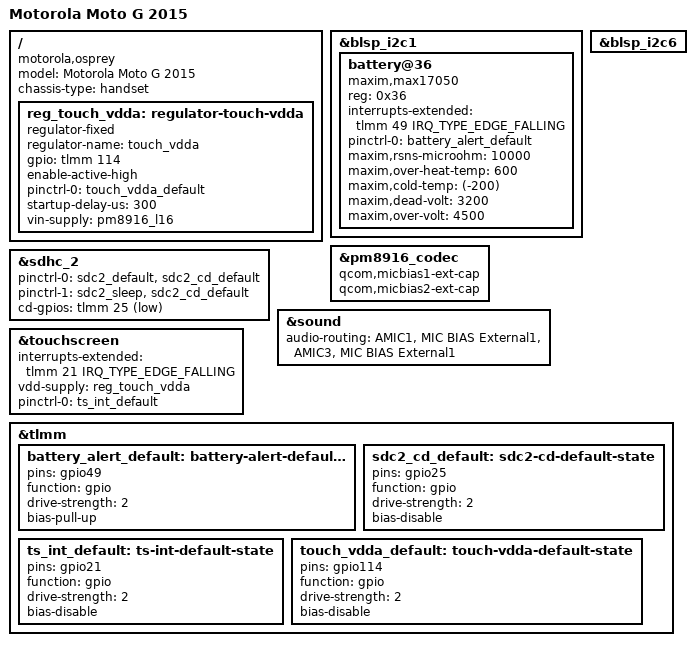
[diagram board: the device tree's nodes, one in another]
// SPDX-License-Identifier: GPL-2.0-only

/dts-v1/;

#include "msm8916-motorola-common.dtsi"

/ {
	model = "Motorola Moto G 2015";
	compatible = "motorola,osprey", "qcom,msm8916";
	chassis-type = "handset";

	reg_touch_vdda: regulator-touch-vdda {
		compatible = "regulator-fixed";
		regulator-name = "touch_vdda";
		gpio = <&tlmm 114 GPIO_ACTIVE_HIGH>;
		enable-active-high;
		pinctrl-0 = <&touch_vdda_default>;
		pinctrl-names = "default";
		startup-delay-us = <300>;
		vin-supply = <&pm8916_l16>;
	};
};

&blsp_i2c1 {
	status = "okay";

	battery@36 {
		compatible = "maxim,max17050";
		reg = <0x36>;

		interrupts-extended = <&tlmm 49 IRQ_TYPE_EDGE_FALLING>;

		pinctrl-0 = <&battery_alert_default>;
		pinctrl-names = "default";

		maxim,rsns-microohm = <10000>;
		maxim,over-heat-temp = <600>;
		maxim,cold-temp = <(-200)>;
		maxim,dead-volt = <3200>;
		maxim,over-volt = <4500>;

	};
};

&blsp_i2c6 {
	/* magnetometer@c */
};

&pm8916_codec {
	qcom,micbias1-ext-cap;
	qcom,micbias2-ext-cap;
};

&sdhc_2 {
	pinctrl-0 = <&sdc2_default &sdc2_cd_default>;
	pinctrl-1 = <&sdc2_sleep &sdc2_cd_default>;
	pinctrl-names = "default", "sleep";

	cd-gpios = <&tlmm 25 GPIO_ACTIVE_LOW>;
};

&sound {
	audio-routing =
		"AMIC1", "MIC BIAS External1",
		"AMIC3", "MIC BIAS External1";
};

&touchscreen {
	interrupts-extended = <&tlmm 21 IRQ_TYPE_EDGE_FALLING>;

	vdd-supply = <&reg_touch_vdda>;

	pinctrl-0 = <&ts_int_default>;
	pinctrl-names = "default";
};

&tlmm {
	battery_alert_default: battery-alert-default-state {
		pins = "gpio49";
		function = "gpio";
		drive-strength = <2>;
		bias-pull-up;
	};

	sdc2_cd_default: sdc2-cd-default-state {
		pins = "gpio25";
		function = "gpio";
		drive-strength = <2>;
		bias-disable;
	};

	ts_int_default: ts-int-default-state {
		pins = "gpio21";
		function = "gpio";
		drive-strength = <2>;
		bias-disable;
	};

	touch_vdda_default: touch-vdda-default-state {
		pins = "gpio114";
		function = "gpio";
		drive-strength = <2>;
		bias-disable;
	};
};
